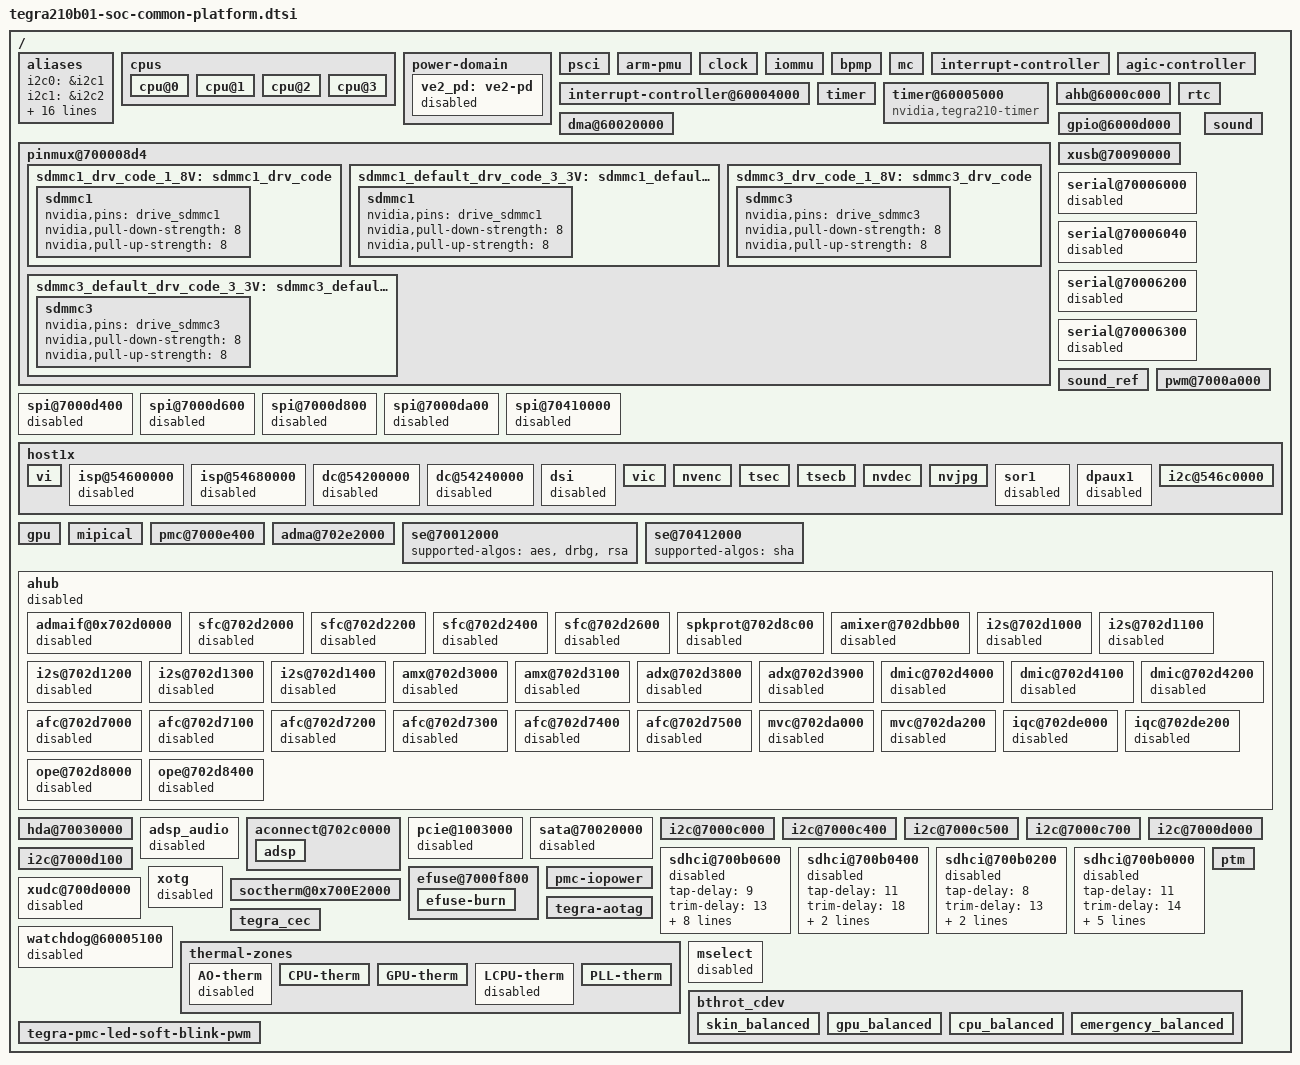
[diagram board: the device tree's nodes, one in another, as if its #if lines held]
/*
 * tegra210b01-soc-common-platform.dtsi: Enabled node common for all platforms.
 *
 * Copyright (c) 2017-2018, NVIDIA CORPORATION.  All rights reserved.
 *
 * This program is free software; you can redistribute it and/or modify
 * it under the terms of the GNU General Public License as published by
 * the Free Software Foundation; version 2 of the License.
 *
 * This program is distributed in the hope that it will be useful, but WITHOUT
 * ANY WARRANTY; without even the implied warranty of MERCHANTABILITY or
 * FITNESS FOR A PARTICULAR PURPOSE.  See the GNU General Public License for
 * more details.
 */

#include "tegra210b01-soc-base.dtsi"
#include "tegra210-soc/tegra210-bthrot-cdev.dtsi"
#include <tegra210-soc/tegra210-sdhci.dtsi>
#include "tegra210b01-soc-prods.dtsi"
#include <dt-bindings/soc/tegra-pmc.h>

/ {
	aliases {
		i2c0 = &i2c1;
		i2c1 = &i2c2;
		i2c2 = &i2c3;
		i2c3 = &i2c4;
		i2c4 = &i2c5;
		i2c5 = &i2c6;
		i2c6 = &i2c7;
		spi0 = &spi0;
		spi1 = &spi1;
		spi2 = &spi2;
		spi3 = &spi3;
		qspi6 = &qspi6;
		serial0 = &uarta;
		serial1 = &uartb;
		serial2 = &uartc;
		serial3 = &uartd;
		rtc0 = "/i2c@7000d000/max77620@3c";
		rtc1 = "/rtc";
	};

	cpus {
		status = "okay";

		cpu@0 {
			status = "okay";
		};

		cpu@1 {
			status = "okay";
		};

		cpu@2 {
			status = "okay";
		};

		cpu@3 {
			status = "okay";
		};
	};

	power-domain {
		ve2_pd: ve2-pd {
			status = "disabled";
		};
	};

	psci {
		status = "okay";
	};

	arm-pmu {
		status = "okay";
	};

	clock {
		status = "okay";
	};

	iommu {
		status = "okay";
	};

	bpmp {
		status = "okay";
	};

	mc {
		status = "okay";
	};

	interrupt-controller {
		status = "okay";
	};

	interrupt-controller@60004000 {
		status = "okay";
	};

	agic-controller {
		status = "okay";
	};

	timer {
		status = "okay";
	};

	timer@60005000 {
		compatible = "nvidia,tegra210-timer", "nvidia,tegra30-timer";
		status = "okay";
	};

	ahb@6000c000 {
		status = "okay";
	};

	rtc {
		status = "okay";
	};

	dma@60020000 {
		status = "okay";
	};

	pinmux@700008d4 {
		status = "okay";
		sdmmc1_drv_code_1_8V: sdmmc1_drv_code {
			sdmmc1 {
				nvidia,pins = "drive_sdmmc1";
				nvidia,pull-down-strength = <8>;
				nvidia,pull-up-strength = <8>;
			};
		};

		sdmmc1_default_drv_code_3_3V: sdmmc1_default_drv_code {
			sdmmc1 {
				nvidia,pins = "drive_sdmmc1";
				nvidia,pull-down-strength = <8>;
				nvidia,pull-up-strength = <8>;
			};
		};

		sdmmc3_drv_code_1_8V: sdmmc3_drv_code {
			sdmmc3 {
				nvidia,pins = "drive_sdmmc3";
				nvidia,pull-down-strength = <8>;
				nvidia,pull-up-strength = <8>;
			};
		};

		sdmmc3_default_drv_code_3_3V: sdmmc3_default_drv_code {
			sdmmc3 {
				nvidia,pins = "drive_sdmmc3";
				nvidia,pull-down-strength = <8>;
				nvidia,pull-up-strength = <8>;
			};
		};
        };

	gpio@6000d000 {
		status = "okay";
        };

	xusb@70090000 {
		status = "okay";
	};

	serial@70006000 {
		status = "disabled";
	};

	serial@70006040 {
		status = "disabled";
	};

	serial@70006200 {
		status = "disabled";
	};

	serial@70006300 {
		status = "disabled";
	};

	sound {
		status = "okay";
	};

	sound_ref {
		status = "okay";
	};

	pwm@7000a000 {
		status = "okay";
	};

	spi@7000d400 {
		status = "disabled";
	};

	spi@7000d600 {
		status = "disabled";
	};

	spi@7000d800 {
		status = "disabled";
	};

	spi@7000da00 {
		status = "disabled";
	};

	spi@70410000 {
		status = "disabled";
	};

	host1x {
		status = "okay";
		vi {
			status = "okay";
		};

		isp@54600000 {
			status = "disabled";
		};

		isp@54680000 {
			status = "disabled";
		};

		dc@54200000 {
			status = "disabled";
		};

		dc@54240000 {
			status = "disabled";
		};

		dsi {
			status = "disabled";
		};

		vic {
			status = "okay";
		};

		nvenc {
			status = "okay";
		};

		tsec {
			status = "okay";
		};

		tsecb {
			status = "okay";
		};

		nvdec {
			status = "okay";
		};

		nvjpg {
			status = "okay";
		};

		sor1 {
			status = "disabled";
		};

		dpaux1 {
			status = "disabled";
		};

		i2c@546c0000 {
			status = "okay";
		};
	};

	gpu {
		status = "okay";
	};

	mipical {
		status = "okay";
	};

	pmc@7000e400 {
		status = "okay";
	};

	adma@702e2000 {
		status = "okay";
	};

	se@70012000 {
		supported-algos = "aes", "drbg", "rsa";
		status = "okay";
	};

	se@70412000 {
		supported-algos = "sha";
		status = "okay";
	};

	ahub {
		status = "disabled";
		admaif@0x702d0000 {
			status = "disabled";
		};

		sfc@702d2000 {
			status = "disabled";
		};

		sfc@702d2200 {
			status = "disabled";
		};

		sfc@702d2400 {
			status = "disabled";
		};

		sfc@702d2600 {
			status = "disabled";
		};

		spkprot@702d8c00 {
			status = "disabled";
		};

		amixer@702dbb00 {
			status = "disabled";
		};

		i2s@702d1000 {
			status = "disabled";
		};

		i2s@702d1100 {
			status = "disabled";
		};

		i2s@702d1200 {
			status = "disabled";
		};

		i2s@702d1300 {
			status = "disabled";
		};

		i2s@702d1400 {
			status = "disabled";
		};

		amx@702d3000 {
			status = "disabled";
		};

		amx@702d3100 {
			status = "disabled";
		};

		adx@702d3800 {
			status = "disabled";
		};

		adx@702d3900 {
			status = "disabled";
		};

		dmic@702d4000 {
			status = "disabled";
		};

		dmic@702d4100 {
			status = "disabled";
		};

		dmic@702d4200 {
			status = "disabled";
		};

		afc@702d7000 {
			status = "disabled";
		};

		afc@702d7100 {
			status = "disabled";
		};

		afc@702d7200 {
			status = "disabled";
		};

		afc@702d7300 {
			status = "disabled";
		};

		afc@702d7400 {
			status = "disabled";
		};

		afc@702d7500 {
			status = "disabled";
		};

		mvc@702da000 {
			status = "disabled";
		};

		mvc@702da200 {
			status = "disabled";
		};

		iqc@702de000 {
			status = "disabled";
		};

		iqc@702de200 {
                        status = "disabled";
                };

		ope@702d8000 {
			status = "disabled";
		};

		ope@702d8400 {
			status = "disabled";
		};
	};

	hda@70030000 {
		status = "okay";
	};

	adsp_audio {
		status = "disabled";
	};

#if TEGRA_AUDIO_BUS_DT_VERSION >= DT_VERSION_2
	aconnect@702c0000 {
#endif

	adsp {
		status = "okay";
	};

#if TEGRA_AUDIO_BUS_DT_VERSION >= DT_VERSION_2
	};
#endif

	pcie@1003000 {
		status = "disabled";
	};

	sata@70020000 {
		status = "disabled";
	};

	i2c@7000c000 {
		status = "okay";
	};

	i2c@7000c400 {
		status = "okay";
	};

	i2c@7000c500 {
		status = "okay";
	};

	i2c@7000c700 {
		status = "okay";
	};

	i2c@7000d000 {
		status = "okay";
	};

	i2c@7000d100 {
		status = "okay";
	};

	sdhci@700b0600 {
		tap-delay = <9>;
		trim-delay = <13>;
		dqs-trim-delay = <40>;
		nvidia,min-tap-delay = <91>;
		nvidia,max-tap-delay = <149>;
		pll_source = "pll_p", "pll_c4_out2";
		clocks = <&tegra_car TEGRA210_CLK_SDMMC4>,
		       <&tegra_car TEGRA210_CLK_PLL_P>,
		       <&tegra_car TEGRA210_CLK_PLL_C4_OUT2>,
			<&tegra_car TEGRA210_CLK_SDMMC_LEGACY>;
		clock-names = "sdmmc", "pll_p", "pll_c4_out2", "sdmmc_legacy_tm";
		status = "disabled";
	};

	sdhci@700b0400 {
		tap-delay = <11>;
		trim-delay = <18>;
		nvidia,min-tap-delay = <91>;
		nvidia,max-tap-delay = <149>;
		status = "disabled";
	};

	sdhci@700b0200 {
		tap-delay = <8>;
		trim-delay = <13>;
		nvidia,min-tap-delay = <91>;
		nvidia,max-tap-delay = <149>;
		status = "disabled";
	};

	sdhci@700b0000 {
		tap-delay = <11>;
		trim-delay = <14>;
		nvidia,cd-wakeup-capable;
		nvidia,min-tap-delay = <91>;
		nvidia,max-tap-delay = <149>;
		nvidia,pmc-wakeup = <&tegra_pmc
			PMC_WAKE_TYPE_EVENT 35 (PMC_TRIGGER_TYPE_RISING | PMC_TRIGGER_TYPE_FALLING)>;
		status = "disabled";
	};

	efuse@7000f800 {
		status = "okay";

		efuse-burn {
			status = "okay";
		};
	};

	pmc-iopower {
		status = "okay";
	};

	xudc@700d0000 {
		status = "disabled";
	};

	xotg {
		status = "disabled";
	};

	soctherm@0x700E2000 {
		status = "okay";
	};

	tegra-aotag {
		status = "okay";
	};

	tegra_cec {
		status = "okay";
	};

	watchdog@60005100 {
		status = "disabled";
	};

	ptm {
		status = "okay";
	};

	thermal-zones {
		AO-therm {
			status = "disabled";
		};

		CPU-therm {
			status = "okay";
		};
		GPU-therm {
			status = "okay";
		};
		LCPU-therm {
			status = "disabled";
		};
		PLL-therm {
			status = "okay";
		};
	};

	mselect {
		status = "disabled";
	};

	bthrot_cdev {
		skin_balanced {
			status = "okay";
		};
		gpu_balanced {
			status = "okay";
		};
		cpu_balanced {
			status = "okay";
		};
		emergency_balanced {
			status = "okay";
		};
	};

	tegra-pmc-led-soft-blink-pwm {
                status = "okay";
	};
};
